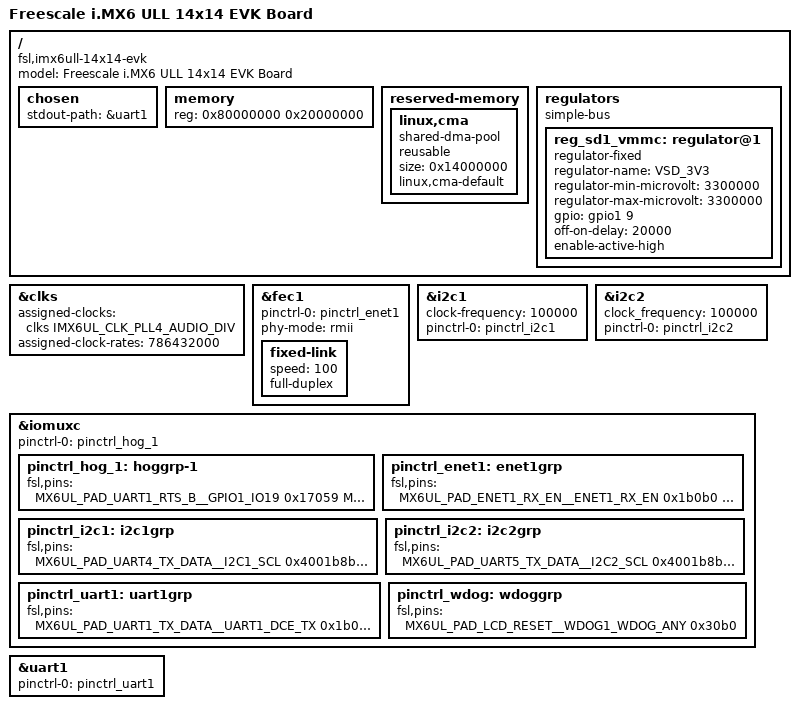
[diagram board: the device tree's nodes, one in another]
/*
 * Copyright (C) 2016 Freescale Semiconductor, Inc.
 *
 * This program is free software; you can redistribute it and/or modify
 * it under the terms of the GNU General Public License version 2 as
 * published by the Free Software Foundation.
 * Edward K. 
 * 	14.11.2017:		The file adapted to Siklu PCB-19x HW boards
 *  18.12.2017:		Minimal DTS without most of drivers. Linux boot-up
 * 					on Siklu board 
 */

/dts-v1/;

#include <dt-bindings/input/input.h>
#include "imx6ull.dtsi"

/ {
	model = "Freescale i.MX6 ULL 14x14 EVK Board";
	compatible = "fsl,imx6ull-14x14-evk", "fsl,imx6ull";

	chosen {
		stdout-path = &uart1; 
	};

	memory {
		reg = <0x80000000 0x20000000>;
	};

	reserved-memory {
		#address-cells = <1>;
		#size-cells = <1>;
		ranges;

		linux,cma {
			compatible = "shared-dma-pool";
			reusable;
			size = <0x14000000>;
			linux,cma-default;
		};
	};


	regulators {
		compatible = "simple-bus";
		#address-cells = <1>;
		#size-cells = <0>;

		reg_sd1_vmmc: regulator@1 {
			compatible = "regulator-fixed";
			regulator-name = "VSD_3V3";
			regulator-min-microvolt = <3300000>;
			regulator-max-microvolt = <3300000>;
			gpio = <&gpio1 9 GPIO_ACTIVE_HIGH>;
			off-on-delay = <20000>;
			enable-active-high;
		};
	};



};

&clks {
	assigned-clocks = <&clks IMX6UL_CLK_PLL4_AUDIO_DIV>;
	assigned-clock-rates = <786432000>;
};


&fec1 {
	pinctrl-names = "default";
	pinctrl-0 = <&pinctrl_enet1>;
	phy-mode = "rmii";
	/* phy-handle = <&ethphy0>; 
	status = "okay"; */
	fixed-link { 
		speed = <100>;
		full-duplex;
	};
};


&i2c1 {
	clock-frequency = <100000>;
	pinctrl-names = "default";
	pinctrl-0 = <&pinctrl_i2c1>;
	status = "okay";

};

&i2c2 {
	clock_frequency = <100000>;
	pinctrl-names = "default";
	pinctrl-0 = <&pinctrl_i2c2>;
	status = "okay";

};

&iomuxc {
	pinctrl-names = "default";
	pinctrl-0 = <&pinctrl_hog_1>;
	pinctrl_hog_1: hoggrp-1 {
		fsl,pins = <
			MX6UL_PAD_UART1_RTS_B__GPIO1_IO19	0x17059 /* SD1 CD */
			MX6UL_PAD_GPIO1_IO05__USDHC1_VSELECT	0x17059 /* SD1 VSELECT */
			MX6UL_PAD_GPIO1_IO09__GPIO1_IO09        0x17059 /* SD1 RESET */
		>;
	};


	pinctrl_enet1: enet1grp {
		fsl,pins = <
			MX6UL_PAD_ENET1_RX_EN__ENET1_RX_EN	0x1b0b0
			MX6UL_PAD_ENET1_RX_ER__ENET1_RX_ER	0x1b0b0
			MX6UL_PAD_ENET1_RX_DATA0__ENET1_RDATA00	0x1b0b0
			MX6UL_PAD_ENET1_RX_DATA1__ENET1_RDATA01	0x1b0b0
			MX6UL_PAD_ENET1_TX_EN__ENET1_TX_EN	0x1b0b0
			MX6UL_PAD_ENET1_TX_DATA0__ENET1_TDATA00	0x1b0b0
			MX6UL_PAD_ENET1_TX_DATA1__ENET1_TDATA01	0x1b0b0
			MX6UL_PAD_ENET1_TX_CLK__ENET1_REF_CLK1	0x4001b031
		>;
	};


	pinctrl_i2c1: i2c1grp {
		fsl,pins = <
			MX6UL_PAD_UART4_TX_DATA__I2C1_SCL 0x4001b8b0
			MX6UL_PAD_UART4_RX_DATA__I2C1_SDA 0x4001b8b0
		>;
	};

	pinctrl_i2c2: i2c2grp {
		fsl,pins = <
			MX6UL_PAD_UART5_TX_DATA__I2C2_SCL 0x4001b8b0
			MX6UL_PAD_UART5_RX_DATA__I2C2_SDA 0x4001b8b0
		>;
	};



	pinctrl_uart1: uart1grp {
		fsl,pins = <
			MX6UL_PAD_UART1_TX_DATA__UART1_DCE_TX 0x1b0b1
			MX6UL_PAD_UART1_RX_DATA__UART1_DCE_RX 0x1b0b1
		>;
	};


	pinctrl_wdog: wdoggrp {
		fsl,pins = <
			MX6UL_PAD_LCD_RESET__WDOG1_WDOG_ANY    0x30b0
		>;
	};
};




&uart1 {
	pinctrl-names = "default";
	pinctrl-0 = <&pinctrl_uart1>;
	status = "okay";
};


